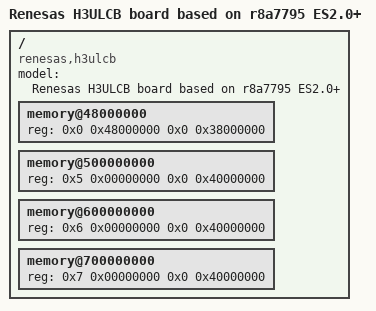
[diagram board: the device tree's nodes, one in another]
/*
 * Device Tree Source for the H3ULCB (R-Car Starter Kit Premier) board
 *
 * Copyright (C) 2016 Renesas Electronics Corp.
 * Copyright (C) 2016 Cogent Embedded, Inc.
 *
 * This file is licensed under the terms of the GNU General Public License
 * version 2.  This program is licensed "as is" without any warranty of any
 * kind, whether express or implied.
 */

#define CPG_AUDIO_CLK_I		R8A7795_CLK_S0D4

/dts-v1/;
#include "r8a7795.dtsi"
#include "ulcb.dtsi"

/ {
	model = "Renesas H3ULCB board based on r8a7795 ES2.0+";
	compatible = "renesas,h3ulcb", "renesas,r8a7795";

	memory@48000000 {
		device_type = "memory";
		/* first 128MB is reserved for secure area. */
		reg = <0x0 0x48000000 0x0 0x38000000>;
	};

	memory@500000000 {
		device_type = "memory";
		reg = <0x5 0x00000000 0x0 0x40000000>;
	};

	memory@600000000 {
		device_type = "memory";
		reg = <0x6 0x00000000 0x0 0x40000000>;
	};

	memory@700000000 {
		device_type = "memory";
		reg = <0x7 0x00000000 0x0 0x40000000>;
	};
};
